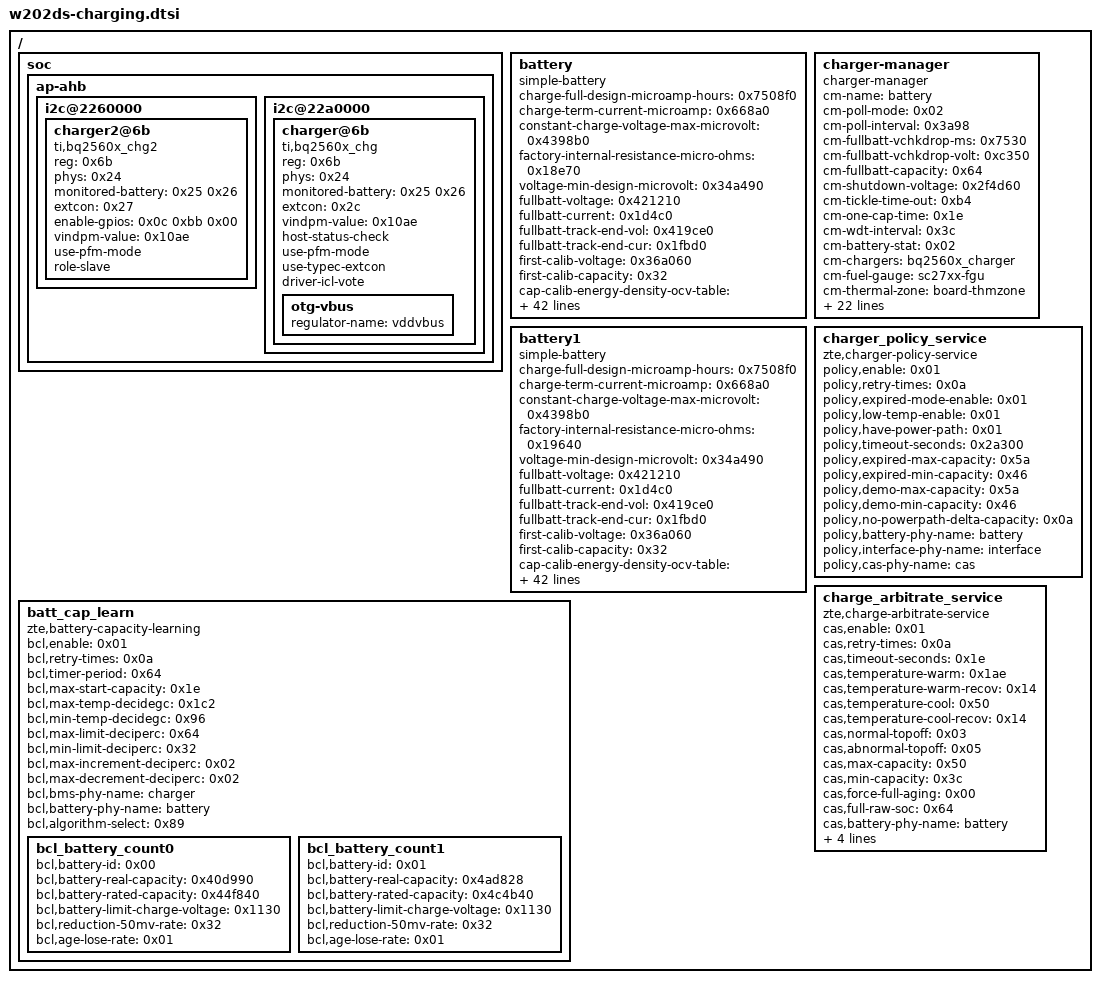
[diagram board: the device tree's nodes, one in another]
// W202DS Server hardware layout; split from the validated imported tree.
/ {
	soc {
		ap-ahb {
			i2c@2260000 {
				charger2@6b {
					compatible = "ti,bq2560x_chg2";
					reg = <0x6b>;
					phys = <0x24>;
					monitored-battery = <0x25 0x26>;
					extcon = <0x27>;
					enable-gpios = <0x0c 0xbb 0x00>;
					vindpm-value = <0x10ae>;
					use-pfm-mode;
					role-slave;
					phandle = <0x14c>;
				};
			};
			i2c@22a0000 {
				charger@6b {
					compatible = "ti,bq2560x_chg";
					reg = <0x6b>;
					phys = <0x24>;
					monitored-battery = <0x25 0x26>;
					extcon = <0x2c>;
					vindpm-value = <0x10ae>;
					host-status-check;
					use-pfm-mode;
					use-typec-extcon;
					driver-icl-vote;
					phandle = <0x152>;
					otg-vbus {
						regulator-name = "vddvbus";
						phandle = <0x7a>;
					};
				};
			};
		};
	};
	battery {
		compatible = "simple-battery";
		charge-full-design-microamp-hours = <0x7508f0>;
		charge-term-current-microamp = <0x668a0>;
		constant-charge-voltage-max-microvolt = <0x4398b0>;
		factory-internal-resistance-micro-ohms = <0x18e70>;
		voltage-min-design-microvolt = <0x34a490>;
		fullbatt-voltage = <0x421210>;
		fullbatt-current = <0x1d4c0>;
		fullbatt-track-end-vol = <0x419ce0>;
		fullbatt-track-end-cur = <0x1fbd0>;
		first-calib-voltage = <0x36a060>;
		first-calib-capacity = <0x32>;
		cap-calib-energy-density-ocv-table = <0x331df0 0x39fbc0 0x3f52f0 0x426030>;
		cap-track-energy-density-ocv-table = <0x33e140 0x38cb10>;
		ocv-capacity-celsius = <0x19>;
		ocv-capacity-table-0 = <0x42e8e8 0x64 0x420658 0x5f 0x4127b0 0x5a 0x404138 0x55 0x3f6290 0x50 0x3e8bb8 0x4b 0x3dc868 0x46 0x3d10d0 0x41 0x3c68d8 0x3c 0x3b7a90 0x37 0x3af1d8 0x32 0x3a8c48 0x2d 0x3a3a40 0x28 0x39f7d8 0x23 0x39c128 0x1e 0x396f20 0x19 0x391d18 0x14 0x38bb70 0x0f 0x384e10 0x0a 0x382318 0x05 0x33e140 0x00>;
		voltage-temp-table = <0x1848b1 0x2ee 0x17bb56 0x320 0x1712f0 0x352 0x16444c 0x384 0x154cae 0x3b6 0x142cc3 0x3e8 0x12e6b7 0x41a 0x1180ec 0x44c 0x10043a 0x47e 0xe7b59 0x4b0 0xcf220 0x4e2 0xb736f 0x514 0xa08a1 0x546 0x8b891 0x578 0x787ce 0x5aa 0x677a5 0x5dc 0x58891 0x60e 0x4b8b6 0x640 0x4059e 0x672 0x360fe 0x6a4 0x2e034 0x6d6>;
		capacity-temp-table = <0x19 0x64 0x0a 0x64 0x00 0x62 0xfffffff6 0x5c 0xffffffec 0x4d>;
		resistance-temp-table = <0x19 0x64 0x0a 0x93 0x00 0x35b 0xfffffff6 0x46e 0xffffffec 0x507>;
		charge-sdp-current-microamp = <0xaae60 0x7a120>;
		charge-dcp-current-microamp = <0x33e140 0x1e8480>;
		charge-cdp-current-microamp = <0x33e140 0x16e360>;
		charge-unknown-current-microamp = <0xf4240 0xf4240>;
		dcp-jeita-temp-table = <0x3e8 0x406 0x00 0x4398b0 0x44c 0x438 0x16e360 0x4398b0 0x47e 0x49c 0x16e360 0x4398b0 0x5aa 0x58c 0x50df20 0x4398b0 0x60e 0x5f0 0x39fbc0 0x3e8fa0>;
		sdp-jeita-temp-table = <0x3e8 0x406 0x00 0x4398b0 0x44c 0x438 0x16e360 0x4398b0 0x47e 0x49c 0x16e360 0x4398b0 0x5aa 0x58c 0x50df20 0x4398b0 0x60e 0x5f0 0x39fbc0 0x3e8fa0>;
		cdp-jeita-temp-table = <0x3e8 0x406 0x00 0x4398b0 0x44c 0x438 0x16e360 0x4398b0 0x47e 0x49c 0x16e360 0x4398b0 0x5aa 0x58c 0x50df20 0x4398b0 0x60e 0x5f0 0x39fbc0 0x3e8fa0>;
		unknown-jeita-temp-table = <0x3e8 0x406 0x00 0x4398b0 0x44c 0x438 0x16e360 0x4398b0 0x47e 0x49c 0x16e360 0x4398b0 0x5aa 0x58c 0x50df20 0x4398b0 0x60e 0x5f0 0x39fbc0 0x3e8fa0>;
		force-jeita-status = <0x02>;
		constant-charge-current-max-microamp = <0x50df20>;
		fast-charge-threshold-microvolt = <0x3e8fa0>;
		ir-cv-offset-microvolt = <0x186a0>;
		ir-rc-micro-ohms = <0x4e20>;
		ir-us-upper-limit-microvolt = <0x44aa20>;
		batt-id-list = <0x2f 0x79>;
		charge-full-microamp-hours = <0x6f2cf0>;
		fullbatt-advance-level = <0x3ca>;
		charge-fchg-current-microamp = <0x286f90 0x1312d0>;
		charge-flash-current-microamp = <0x286f90 0x1312d0>;
		fchg-jeita-temp-table = <0x3e8 0x406 0x00 0x4398b0 0x44c 0x438 0x16e360 0x4398b0 0x47e 0x49c 0x16e360 0x4398b0 0x5aa 0x58c 0x50df20 0x4398b0 0x60e 0x5f0 0x39fbc0 0x3e8fa0>;
		flash-jeita-temp-table = <0x3e8 0x406 0x00 0x4398b0 0x44c 0x438 0x16e360 0x4398b0 0x47e 0x49c 0x16e360 0x4398b0 0x5aa 0x58c 0x50df20 0x4398b0 0x60e 0x5f0 0x39fbc0 0x3e8fa0>;
		phandle = <0x25>;
	};
	battery1 {
		compatible = "simple-battery";
		charge-full-design-microamp-hours = <0x7508f0>;
		charge-term-current-microamp = <0x668a0>;
		constant-charge-voltage-max-microvolt = <0x4398b0>;
		factory-internal-resistance-micro-ohms = <0x19640>;
		voltage-min-design-microvolt = <0x34a490>;
		fullbatt-voltage = <0x421210>;
		fullbatt-current = <0x1d4c0>;
		fullbatt-track-end-vol = <0x419ce0>;
		fullbatt-track-end-cur = <0x1fbd0>;
		first-calib-voltage = <0x36a060>;
		first-calib-capacity = <0x32>;
		cap-calib-energy-density-ocv-table = <0x331df0 0x39fbc0 0x3f52f0 0x426030>;
		cap-track-energy-density-ocv-table = <0x33e140 0x38cb10>;
		ocv-capacity-celsius = <0x19>;
		ocv-capacity-table-0 = <0x42e118 0x64 0x420e28 0x5f 0x412f80 0x5a 0x404cf0 0x55 0x3f6e48 0x50 0x3e9b58 0x4b 0x3dd420 0x46 0x3d1c88 0x41 0x3c7878 0x3c 0x3b8260 0x37 0x3afd90 0x32 0x3a9800 0x2d 0x3a45f8 0x28 0x39ffa8 0x23 0x39c510 0x1e 0x396b38 0x19 0x391d18 0x14 0x38bb70 0x0f 0x384e10 0x0a 0x382318 0x05 0x33e140 0x00>;
		voltage-temp-table = <0x1848b1 0x2ee 0x17bb56 0x320 0x1712f0 0x352 0x16444c 0x384 0x154cae 0x3b6 0x142cc3 0x3e8 0x12e6b7 0x41a 0x1180ec 0x44c 0x10043a 0x47e 0xe7b59 0x4b0 0xcf220 0x4e2 0xb736f 0x514 0xa08a1 0x546 0x8b891 0x578 0x787ce 0x5aa 0x677a5 0x5dc 0x58891 0x60e 0x4b8b6 0x640 0x4059e 0x672 0x360fe 0x6a4 0x2e034 0x6d6>;
		capacity-temp-table = <0x19 0x64 0x0a 0x63 0x00 0x63 0xfffffff6 0x5f 0xffffffec 0x51>;
		resistance-temp-table = <0x19 0x64 0x0a 0x92 0x00 0x2d1 0xfffffff6 0x431 0xffffffec 0x4e1>;
		charge-sdp-current-microamp = <0xaae60 0x7a120>;
		charge-dcp-current-microamp = <0x50df20 0x1e8480>;
		charge-cdp-current-microamp = <0x50df20 0x16e360>;
		charge-unknown-current-microamp = <0xf4240 0xf4240>;
		dcp-jeita-temp-table = <0x3e8 0x406 0x00 0x4398b0 0x44c 0x438 0x16e360 0x4398b0 0x47e 0x49c 0x16e360 0x4398b0 0x5aa 0x58c 0x50df20 0x4398b0 0x60e 0x5f0 0x39fbc0 0x3e8fa0>;
		sdp-jeita-temp-table = <0x3e8 0x406 0x00 0x4398b0 0x44c 0x438 0x16e360 0x4398b0 0x47e 0x49c 0x16e360 0x4398b0 0x5aa 0x58c 0x50df20 0x4398b0 0x60e 0x5f0 0x39fbc0 0x3e8fa0>;
		cdp-jeita-temp-table = <0x3e8 0x406 0x00 0x4398b0 0x44c 0x438 0x16e360 0x4398b0 0x47e 0x49c 0x16e360 0x4398b0 0x5aa 0x58c 0x50df20 0x4398b0 0x60e 0x5f0 0x39fbc0 0x3e8fa0>;
		unknown-jeita-temp-table = <0x3e8 0x406 0x00 0x4398b0 0x44c 0x438 0x16e360 0x4398b0 0x47e 0x49c 0x16e360 0x4398b0 0x5aa 0x58c 0x50df20 0x4398b0 0x60e 0x5f0 0x39fbc0 0x3e8fa0>;
		force-jeita-status = <0x02>;
		constant-charge-current-max-microamp = <0x50df20>;
		fast-charge-threshold-microvolt = <0x3e8fa0>;
		ir-cv-offset-microvolt = <0x186a0>;
		ir-rc-micro-ohms = <0x4e20>;
		ir-us-upper-limit-microvolt = <0x44aa20>;
		batt-id-list = <0x2f 0x79>;
		charge-full-microamp-hours = <0x6f2cf0>;
		fullbatt-advance-level = <0x3ca>;
		charge-fchg-current-microamp = <0x286f90 0x1312d0>;
		charge-flash-current-microamp = <0x286f90 0x1312d0>;
		fchg-jeita-temp-table = <0x3e8 0x406 0x00 0x4398b0 0x44c 0x438 0x16e360 0x4398b0 0x47e 0x49c 0x16e360 0x4398b0 0x5aa 0x58c 0x50df20 0x4398b0 0x60e 0x5f0 0x39fbc0 0x3e8fa0>;
		flash-jeita-temp-table = <0x3e8 0x406 0x00 0x4398b0 0x44c 0x438 0x16e360 0x4398b0 0x47e 0x49c 0x16e360 0x4398b0 0x5aa 0x58c 0x50df20 0x4398b0 0x60e 0x5f0 0x39fbc0 0x3e8fa0>;
		phandle = <0x26>;
	};
	charger-manager {
		compatible = "charger-manager";
		cm-name = "battery";
		cm-poll-mode = <0x02>;
		cm-poll-interval = <0x3a98>;
		cm-fullbatt-vchkdrop-ms = <0x7530>;
		cm-fullbatt-vchkdrop-volt = <0xc350>;
		cm-fullbatt-capacity = <0x64>;
		cm-shutdown-voltage = <0x2f4d60>;
		cm-tickle-time-out = <0xb4>;
		cm-one-cap-time = <0x1e>;
		cm-wdt-interval = <0x3c>;
		cm-battery-stat = <0x02>;
		cm-chargers = "bq2560x_charger";
		cm-fuel-gauge = "sc27xx-fgu";
		cm-thermal-zone = "board-thmzone";
		cm-battery-cold = <0x00>;
		cm-battery-cold-in-minus;
		cm-battery-hot = <0x226>;
		cm-battery-temp-diff = <0x1e>;
		cm-charging-max = <0x1499700>;
		cm-discharging-max = <0x2932e0>;
		cm-charge-voltage-max = <0x632ea0>;
		cm-charge-voltage-drop = <0xaae60>;
		sprd,support-fchg;
		sprd,support-sfcp;
		sprd,support-pd-pps;
		sprd,pd-fixed-max-microwatt = <0x112a880>;
		use-typec-extcon;
		phys = <0x24>;
		pd-extcon-enable;
		extcon = <0x2c 0x61>;
		cm-hardware-psy = "bq2560x_charger";
		zte-cm-hardware-psy = "zte_bq2560x_charger";
		zte-cm-hardware2-psy = "zte_bq2560x_slave_charger";
		zte-cm-fuel-gauge = "zte-fgu";
		monitored-battery = <0x25 0x26>;
	};
	charger_policy_service {
		compatible = "zte,charger-policy-service";
		status = "okay";
		policy,enable = <0x01>;
		policy,retry-times = <0x0a>;
		policy,expired-mode-enable = <0x01>;
		policy,low-temp-enable = <0x01>;
		policy,have-power-path = <0x01>;
		policy,timeout-seconds = <0x2a300>;
		policy,expired-max-capacity = <0x5a>;
		policy,expired-min-capacity = <0x46>;
		policy,demo-max-capacity = <0x5a>;
		policy,demo-min-capacity = <0x46>;
		policy,no-powerpath-delta-capacity = <0x0a>;
		policy,battery-phy-name = "battery";
		policy,interface-phy-name = "interface";
		policy,cas-phy-name = "cas";
	};
	batt_cap_learn {
		compatible = "zte,battery-capacity-learning";
		bcl,enable = <0x01>;
		bcl,retry-times = <0x0a>;
		bcl,timer-period = <0x64>;
		bcl,max-start-capacity = <0x1e>;
		bcl,max-temp-decidegc = <0x1c2>;
		bcl,min-temp-decidegc = <0x96>;
		bcl,max-limit-deciperc = <0x64>;
		bcl,min-limit-deciperc = <0x32>;
		bcl,max-increment-deciperc = <0x02>;
		bcl,max-decrement-deciperc = <0x02>;
		bcl,bms-phy-name = "charger";
		bcl,battery-phy-name = "battery";
		bcl,algorithm-select = <0x89>;
		bcl_battery_count0 {
			bcl,battery-id = <0x00>;
			bcl,battery-real-capacity = <0x40d990>;
			bcl,battery-rated-capacity = <0x44f840>;
			bcl,battery-limit-charge-voltage = <0x1130>;
			bcl,reduction-50mv-rate = <0x32>;
			bcl,age-lose-rate = <0x01>;
		};
		bcl_battery_count1 {
			bcl,battery-id = <0x01>;
			bcl,battery-real-capacity = <0x4ad828>;
			bcl,battery-rated-capacity = <0x4c4b40>;
			bcl,battery-limit-charge-voltage = <0x1130>;
			bcl,reduction-50mv-rate = <0x32>;
			bcl,age-lose-rate = <0x01>;
		};
	};
	charge_arbitrate_service {
		compatible = "zte,charge-arbitrate-service";
		cas,enable = <0x01>;
		cas,retry-times = <0x0a>;
		cas,timeout-seconds = <0x1e>;
		cas,temperature-warm = <0x1ae>;
		cas,temperature-warm-recov = <0x14>;
		cas,temperature-cool = <0x50>;
		cas,temperature-cool-recov = <0x14>;
		cas,normal-topoff = <0x03>;
		cas,abnormal-topoff = <0x05>;
		cas,max-capacity = <0x50>;
		cas,min-capacity = <0x3c>;
		cas,force-full-aging = <0x00>;
		cas,full-raw-soc = <0x64>;
		cas,battery-phy-name = "battery";
		cas,bcl-phy-name = "bcl";
		cas,interface-phy-name = "interface";
		cas,age-data = <0x64 0x432380 0x4a4f70 0x00 0x00 0x64 0xc8 0x5f 0x42d560 0x2b7cd0 0x00 0x00 0x64 0xc8 0x5a 0x428740 0x2932e0 0x00 0x00 0x64 0xc8 0x55 0x423920 0x26e8f0 0x00 0x00 0xc8 0xc8 0x50 0x41eb00 0x249f00 0x00 0x00 0xc8 0xc8 0x4b 0x419ce0 0x225510 0x00 0x00 0xc8 0xc8>;
	};
	__symbols__ {
		bq2560x_chg2 = "/soc/ap-ahb/i2c@2260000/charger2@6b";
		bq2560x_chg = "/soc/ap-ahb/i2c@22a0000/charger@6b";
		vddvbus = "/soc/ap-ahb/i2c@22a0000/charger@6b/otg-vbus";
		bat = "/battery";
		bat1 = "/battery1";
	};
};
